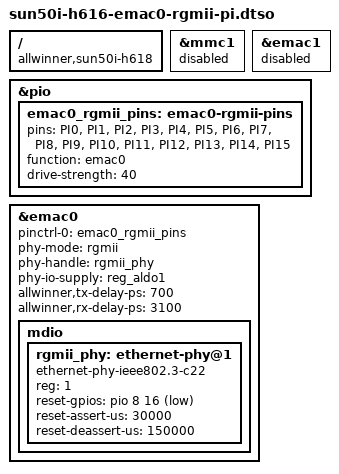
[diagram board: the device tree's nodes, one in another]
/dts-v1/;
/plugin/;

/ {
	compatible = "allwinner,sun50i-h618", "allwinner,sun50i-h616";

	fragment@0 {
		target = <&mmc1>;
		__overlay__ {
			status = "disabled";
		};
	};

	fragment@1 {
		target = <&emac1>;
		__overlay__ {
			status = "disabled";
		};
	};

	fragment@2 {
		target = <&pio>;
		__overlay__ {
			emac0_rgmii_pins: emac0-rgmii-pins {
				pins = "PI0", "PI1", "PI2", "PI3", "PI4",
				       "PI5", "PI6", "PI7", "PI8", "PI9",
				       "PI10", "PI11", "PI12", "PI13",
				       "PI14", "PI15";
				function = "emac0";
				drive-strength = <40>;
			};
		};
	};

	fragment@3 {
		target = <&emac0>;
		__overlay__ {
			pinctrl-names = "default";
			pinctrl-0 = <&emac0_rgmii_pins>;
			phy-mode = "rgmii";
			phy-handle = <&rgmii_phy>;
			phy-io-supply = <&reg_aldo1>;
			allwinner,tx-delay-ps = <700>;
			allwinner,rx-delay-ps = <3100>;
			status = "okay";

			mdio {
				#address-cells = <1>;
				#size-cells = <0>;

				rgmii_phy: ethernet-phy@1 {
					compatible = "ethernet-phy-ieee802.3-c22";
					reg = <1>;
					reset-gpios = <&pio 8 16 1>;
					reset-assert-us = <30000>;
					reset-deassert-us = <150000>;
				};
			};
		};
	};
};
